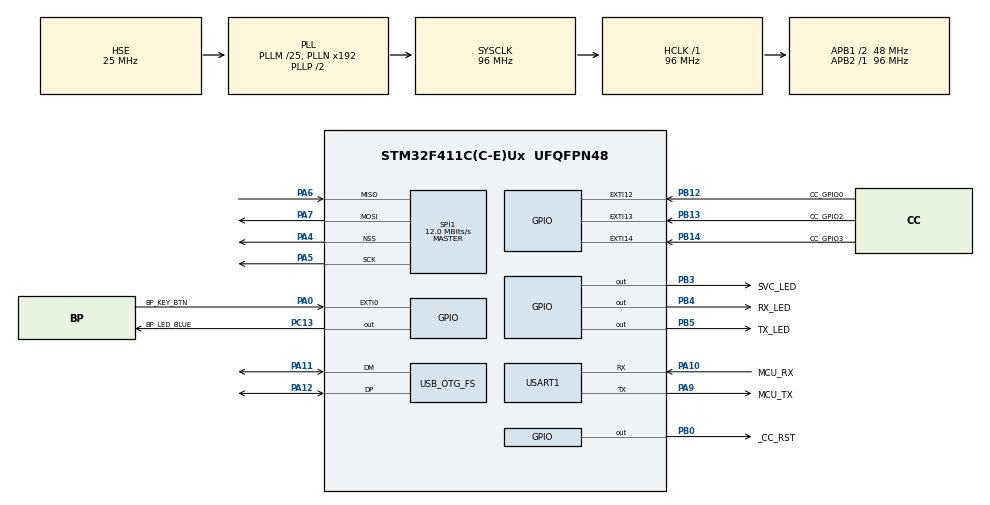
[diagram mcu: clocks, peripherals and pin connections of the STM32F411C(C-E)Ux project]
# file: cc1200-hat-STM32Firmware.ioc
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Dma.Request0=SPI1_RX
Dma.Request1=SPI1_TX
Dma.Request2=USART1_RX
Dma.Request3=USART1_TX
Dma.SPI1_RX.0.Direction=DMA_PERIPH_TO_MEMORY
Dma.SPI1_RX.0.FIFOMode=DMA_FIFOMODE_DISABLE
Dma.SPI1_RX.0.Instance=DMA2_Stream0
Dma.SPI1_RX.0.MemDataAlignment=DMA_MDATAALIGN_BYTE
Dma.SPI1_RX.0.MemInc=DMA_MINC_ENABLE
Dma.SPI1_RX.0.Mode=DMA_NORMAL
Dma.SPI1_RX.0.PeriphDataAlignment=DMA_PDATAALIGN_BYTE
Dma.SPI1_RX.0.PeriphInc=DMA_PINC_DISABLE
Dma.SPI1_RX.0.Priority=DMA_PRIORITY_HIGH
Dma.SPI1_TX.1.Direction=DMA_MEMORY_TO_PERIPH
Dma.SPI1_TX.1.FIFOMode=DMA_FIFOMODE_DISABLE
Dma.SPI1_TX.1.Instance=DMA2_Stream3
Dma.SPI1_TX.1.MemDataAlignment=DMA_MDATAALIGN_BYTE
Dma.SPI1_TX.1.MemInc=DMA_MINC_ENABLE
Dma.SPI1_TX.1.Mode=DMA_NORMAL
Dma.SPI1_TX.1.PeriphDataAlignment=DMA_PDATAALIGN_BYTE
Dma.SPI1_TX.1.PeriphInc=DMA_PINC_DISABLE
Dma.SPI1_TX.1.Priority=DMA_PRIORITY_HIGH
Dma.USART1_RX.2.Direction=DMA_PERIPH_TO_MEMORY
Dma.USART1_RX.2.FIFOMode=DMA_FIFOMODE_DISABLE
Dma.USART1_RX.2.Instance=DMA2_Stream5
Dma.USART1_RX.2.MemDataAlignment=DMA_MDATAALIGN_BYTE
Dma.USART1_RX.2.MemInc=DMA_MINC_ENABLE
Dma.USART1_RX.2.Mode=DMA_NORMAL
Dma.USART1_RX.2.PeriphDataAlignment=DMA_PDATAALIGN_BYTE
Dma.USART1_RX.2.PeriphInc=DMA_PINC_DISABLE
Dma.USART1_RX.2.Priority=DMA_PRIORITY_LOW
Dma.USART1_TX.3.Direction=DMA_MEMORY_TO_PERIPH
Dma.USART1_TX.3.FIFOMode=DMA_FIFOMODE_DISABLE
Dma.USART1_TX.3.Instance=DMA2_Stream7
Dma.USART1_TX.3.MemDataAlignment=DMA_MDATAALIGN_BYTE
Dma.USART1_TX.3.MemInc=DMA_MINC_ENABLE
Dma.USART1_TX.3.Mode=DMA_NORMAL
Dma.USART1_TX.3.PeriphDataAlignment=DMA_PDATAALIGN_BYTE
Dma.USART1_TX.3.PeriphInc=DMA_PINC_DISABLE
Dma.USART1_TX.3.Priority=DMA_PRIORITY_LOW
FREERTOS.BinarySemaphores01=myBinarySem01,Dynamic,NULL
FREERTOS.CountingSemaphores01=myCountingSem01,2,Dynamic,NULL
FREERTOS.Mutexes01=myMutex01,Dynamic,NULL;myMutex02,Dynamic,NULL
FREERTOS.Queues01=myQueue01,16,uint16_t,0,Dynamic,NULL,NULL;myQueue02,16,uint16_t,0,Dynamic,NULL,NULL
FREERTOS.Tasks01=defaultTask,24,128,StartDefaultTask,Default,NULL,Dynamic,NULL,NULL;myTask02,8,128,StartTask02,Default,NULL,Dynamic,NULL,NULL;myTask03,8,128,StartTask03,Default,NULL,Dynamic,NULL,NULL;myTask04,8,128,StartTask04,Default,NULL,Dynamic,NULL,NULL
FREERTOS.Timers01=myTimer01,Callback01,osTimerPeriodic,Default,NULL,Dynamic,NULL
FREERTOS.configUSE_NEWLIB_REENTRANT=1
IWDG.Prescaler=IWDG_PRESCALER_64
Mcu.Family=STM32F4
Mcu.Name=STM32F411C(C-E)Ux
Mcu.Package=UFQFPN48
NVIC.DMA2_Stream0_IRQn=true\:5\:0\:false\:false\:true\:true\:false\:true\:true
NVIC.DMA2_Stream3_IRQn=true\:5\:0\:false\:false\:true\:true\:false\:true\:true
NVIC.DMA2_Stream5_IRQn=true\:5\:0\:false\:false\:true\:true\:false\:true\:true
NVIC.DMA2_Stream7_IRQn=true\:5\:0\:false\:false\:true\:true\:false\:true\:true
NVIC.OTG_FS_IRQn=true\:5\:0\:false\:false\:true\:true\:false\:true\:true
NVIC.PriorityGroup=NVIC_PRIORITYGROUP_4
NVIC.SPI1_IRQn=true\:5\:0\:false\:false\:true\:true\:true\:true\:true
NVIC.TIM1_UP_TIM10_IRQn=true\:5\:0\:false\:false\:true\:false\:false\:true\:true
NVIC.TimeBase=TIM1_UP_TIM10_IRQn
NVIC.TimeBaseIP=TIM1
NVIC.USART1_IRQn=true\:5\:0\:false\:false\:true\:true\:false\:true\:true
PA0-WKUP.GPIO_Label=BP_KEY_BTN
PA0-WKUP.Signal=GPXTI0
PA10.GPIO_Label=MCU_RX
PA10.Mode=Asynchronous
PA10.Signal=USART1_RX
PA11.Mode=Device_Only
PA11.Signal=USB_OTG_FS_DM
PA12.Mode=Device_Only
PA12.Signal=USB_OTG_FS_DP
PA13.Mode=Serial_Wire
PA13.Signal=SYS_JTMS-SWDIO
PA14.Mode=Serial_Wire
PA14.Signal=SYS_JTCK-SWCLK
PA4.Mode=NSS_Signal_Hard_Output
PA4.Signal=SPI1_NSS
PA5.Mode=Full_Duplex_Master
PA5.Signal=SPI1_SCK
PA6.Mode=Full_Duplex_Master
PA6.Signal=SPI1_MISO
PA7.Mode=Full_Duplex_Master
PA7.Signal=SPI1_MOSI
PA9.GPIO_Label=MCU_TX
PA9.Mode=Asynchronous
PA9.Signal=USART1_TX
PB0.GPIO_Label=_CC_RST
PB0.Signal=GPIO_Output
PB12.GPIO_Label=CC_GPIO0
PB12.Signal=GPXTI12
PB13.GPIO_Label=CC_GPIO2
PB13.Signal=GPXTI13
PB14.GPIO_Label=CC_GPIO3
PB14.Signal=GPXTI14
PB3.GPIO_Label=SVC_LED
PB3.Signal=GPIO_Output
PB4.GPIO_Label=RX_LED
PB4.Signal=GPIO_Output
PB5.GPIO_Label=TX_LED
PB5.Signal=GPIO_Output
PC13-ANTI_TAMP.GPIO_Label=BP_LED_BLUE
PC13-ANTI_TAMP.Signal=GPIO_Output
PH0\ -\ OSC_IN.Mode=HSE-External-Oscillator
PH0\ -\ OSC_IN.Signal=RCC_OSC_IN
PH1\ -\ OSC_OUT.Mode=HSE-External-Oscillator
PH1\ -\ OSC_OUT.Signal=RCC_OSC_OUT
ProjectManager.HeapSize=0x200
ProjectManager.StackSize=0x400
ProjectManager.TargetToolchain=STM32CubeIDE
RCC.48MHZClocksFreq_Value=48000000
RCC.AHBFreq_Value=96000000
RCC.APB1CLKDivider=RCC_HCLK_DIV2
RCC.APB1Freq_Value=48000000
RCC.APB1TimFreq_Value=96000000
RCC.APB2Freq_Value=96000000
RCC.APB2TimFreq_Value=96000000
RCC.CortexFreq_Value=96000000
RCC.HCLKFreq_Value=96000000
RCC.HSE_VALUE=25000000
RCC.HSI_VALUE=16000000
RCC.LSE_VALUE=32768
RCC.PLLM=25
RCC.SYSCLKFreq_VALUE=96000000
RCC.SYSCLKSource=RCC_SYSCLKSOURCE_PLLCLK
RCC.VCOOutputFreq_Value=192000000
SPI1.BaudRatePrescaler=SPI_BAUDRATEPRESCALER_8
SPI1.CalculateBaudRate=12.0 MBits/s
SPI1.Direction=SPI_DIRECTION_2LINES
SPI1.Mode=SPI_MODE_MASTER
SPI1.TIMode=SPI_TIMODE_DISABLE
SPI1.VirtualNSS=VM_NSSHARD
SPI1.VirtualType=VM_MASTER
USART1.VirtualMode=VM_ASYNC
USB_DEVICE.CLASS_NAME_FS=CDC
USB_DEVICE.VirtualMode=Cdc
USB_DEVICE.VirtualModeFS=Cdc_FS
USB_OTG_FS.VirtualMode=Device_Only
VP_FREERTOS_VS_CMSIS_V2.Mode=CMSIS_V2
VP_IWDG_VS_IWDG.Mode=IWDG_Activate
VP_SYS_VS_tim1.Mode=TIM1
VP_TIM10_VS_ClockSourceINT.Mode=Enable_Timer
VP_TIM11_VS_ClockSourceINT.Mode=Enable_Timer
VP_USB_DEVICE_VS_USB_DEVICE_CDC_FS.Mode=CDC_FS
board=custom

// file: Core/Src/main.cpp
/* USER CODE BEGIN Header */
/**
  ******************************************************************************
  * @file           : main.c
  * @brief          : Main program body
  ******************************************************************************
  * @attention
  *
  * Copyright (c) 2025 STMicroelectronics.
  * All rights reserved.
  *
  * This software is licensed under terms that can be found in the LICENSE file
  * in the root directory of this software component.
  * If no LICENSE file comes with this software, it is provided AS-IS.
  *
  ******************************************************************************
  */
/* USER CODE END Header */
#include "main.h"
#include "cmsis_os.h"
#include "dma.h"
#include "iwdg.h"
#include "spi.h"
#include "tim.h"
#include "usart.h"
#include "usb_device.h"
#include "gpio.h"
#include "globals.h"

/* USER CODE BEGIN PV */
// Global instance of the Globals class
Globals* globals = nullptr;
/* USER CODE END PV */

extern "C" void SystemClock_Config(void);
void MX_FREERTOS_Init(Globals* globals);

int main(void)
{

  /* MCU Configuration--------------------------------------------------------*/

  /* Reset of all peripherals, Initializes the Flash interface and the Systick. */
  HAL_Init();

  /* Configure the system clock */
  SystemClock_Config();

  /* Initialize all configured peripherals */
  MX_GPIO_Init();
  MX_DMA_Init();
  MX_IWDG_Init();
  MX_SPI1_Init();
  MX_USART1_UART_Init();
  MX_TIM10_Init();
  MX_TIM11_Init();
  /* USER CODE BEGIN 2 */
  // Create the globals instance with the initialized peripheral handles
  globals = new Globals(&huart1, &hiwdg, &hspi1, BP_LED_BLUE_GPIO_Port, BP_LED_BLUE_Pin, BP_KEY_BTN_GPIO_Port, GPIO_PIN_0);
  /* USER CODE END 2 */

  /* Init scheduler */
  osKernelInitialize();

  /* Call init function for freertos objects (in cmsis_os2.c) */
  MX_FREERTOS_Init(globals);

  /* Start scheduler */
  osKernelStart();

  /* We should never get here as control is now taken by the scheduler */

  /* Infinite loop */
  while (1)
  {

  }
}

void SystemClock_Config(void)
{
  RCC_OscInitTypeDef RCC_OscInitStruct = {0};
  RCC_ClkInitTypeDef RCC_ClkInitStruct = {0};

  /** Configure the main internal regulator output voltage
  */
  __HAL_RCC_PWR_CLK_ENABLE();
  __HAL_PWR_VOLTAGESCALING_CONFIG(PWR_REGULATOR_VOLTAGE_SCALE1);

  /** Initializes the RCC Oscillators according to the specified parameters
  * in the RCC_OscInitTypeDef structure.
  */
  RCC_OscInitStruct.OscillatorType = RCC_OSCILLATORTYPE_LSI|RCC_OSCILLATORTYPE_HSE;
  RCC_OscInitStruct.HSEState = RCC_HSE_ON;
  RCC_OscInitStruct.LSIState = RCC_LSI_ON;
  RCC_OscInitStruct.PLL.PLLState = RCC_PLL_ON;
  RCC_OscInitStruct.PLL.PLLSource = RCC_PLLSOURCE_HSE;
  RCC_OscInitStruct.PLL.PLLM = 25;
  RCC_OscInitStruct.PLL.PLLN = 192;
  RCC_OscInitStruct.PLL.PLLP = RCC_PLLP_DIV2;
  RCC_OscInitStruct.PLL.PLLQ = 4;
  if (HAL_RCC_OscConfig(&RCC_OscInitStruct) != HAL_OK)
  {
    Error_Handler();
  }

  /** Initializes the CPU, AHB and APB buses clocks
  */
  RCC_ClkInitStruct.ClockType = RCC_CLOCKTYPE_HCLK|RCC_CLOCKTYPE_SYSCLK
                              |RCC_CLOCKTYPE_PCLK1|RCC_CLOCKTYPE_PCLK2;
  RCC_ClkInitStruct.SYSCLKSource = RCC_SYSCLKSOURCE_PLLCLK;
  RCC_ClkInitStruct.AHBCLKDivider = RCC_SYSCLK_DIV1;
  RCC_ClkInitStruct.APB1CLKDivider = RCC_HCLK_DIV2;
  RCC_ClkInitStruct.APB2CLKDivider = RCC_HCLK_DIV1;

  if (HAL_RCC_ClockConfig(&RCC_ClkInitStruct, FLASH_LATENCY_3) != HAL_OK)
  {
    Error_Handler();
  }
}

void HAL_TIM_PeriodElapsedCallback(TIM_HandleTypeDef *htim)
{
  if (htim->Instance == TIM1) {
    HAL_IncTick();
  }
}

void Error_Handler(void)
{
  __disable_irq();
  while (1)
  {
  }
}
